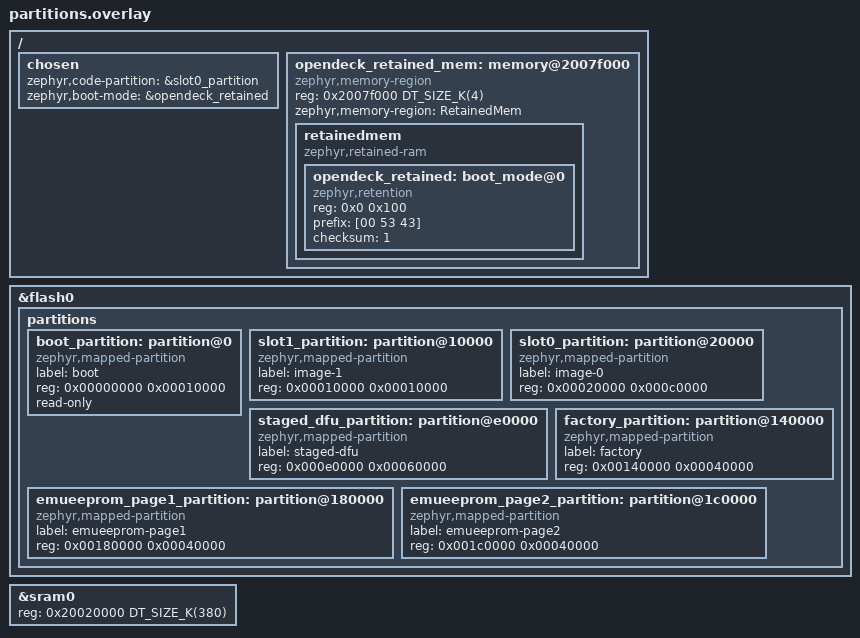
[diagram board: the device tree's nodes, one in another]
&flash0 {
    #address-cells = <1>;
    #size-cells = <1>;
    ranges = <0x0 0x08000000 0x00200000>;

    partitions {
        ranges;
        #address-cells = <1>;
        #size-cells = <1>;

        /delete-node/ partition@0;
        /delete-node/ partition@10000;
        /delete-node/ partition@40000;
        /delete-node/ partition@100000;
        /delete-node/ partition@1c0000;

        boot_partition: partition@0 {
            compatible = "zephyr,mapped-partition";
            label = "boot";
            reg = <0x00000000 0x00010000>;
            read-only;
        };

        /* image-1 is the OpenDeck bootloader; keep it before image-0 so merged images stay compact. */
        slot1_partition: partition@10000 {
            compatible = "zephyr,mapped-partition";
            label = "image-1";
            reg = <0x00010000 0x00010000>;
        };

        slot0_partition: partition@20000 {
            compatible = "zephyr,mapped-partition";
            label = "image-0";
            reg = <0x00020000 0x000c0000>;
        };

        staged_dfu_partition: partition@e0000 {
            compatible = "zephyr,mapped-partition";
            label = "staged-dfu";
            reg = <0x000e0000 0x00060000>;
        };

        factory_partition: partition@140000 {
            compatible = "zephyr,mapped-partition";
            label = "factory";
            reg = <0x00140000 0x00040000>;
        };

        emueeprom_page1_partition: partition@180000 {
            compatible = "zephyr,mapped-partition";
            label = "emueeprom-page1";
            reg = <0x00180000 0x00040000>;
        };

        emueeprom_page2_partition: partition@1c0000 {
            compatible = "zephyr,mapped-partition";
            label = "emueeprom-page2";
            reg = <0x001c0000 0x00040000>;
        };
    };
};

&sram0 {
    reg = <0x20020000 DT_SIZE_K(380)>;
};

/ {
    chosen {
        zephyr,code-partition = &slot0_partition;
        zephyr,boot-mode = &opendeck_retained;
    };

    opendeck_retained_mem: memory@2007f000 {
        compatible = "zephyr,memory-region", "mmio-sram";
        reg = <0x2007f000 DT_SIZE_K(4)>;
        zephyr,memory-region = "RetainedMem";
        status = "okay";

        retainedmem {
            compatible = "zephyr,retained-ram";
            status = "okay";
            #address-cells = <1>;
            #size-cells = <1>;

            opendeck_retained: boot_mode@0 {
                compatible = "zephyr,retention";
                status = "okay";
                reg = <0x0 0x100>;
                prefix = [00 53 43];
                checksum = <1>;
            };
        };
    };
};
